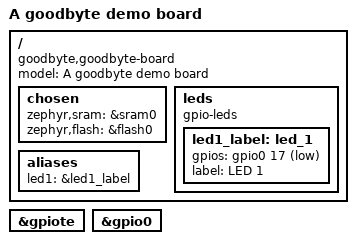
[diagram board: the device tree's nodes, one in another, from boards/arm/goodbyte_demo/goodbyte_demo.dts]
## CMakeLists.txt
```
cmake_minimum_required(VERSION 3.20.0)

list(APPEND BOARD_ROOT ${CMAKE_CURRENT_SOURCE_DIR})
find_package(Zephyr REQUIRED)
project(my_zephyr_app)

target_sources(app
    PRIVATE
        src/main.cpp
)
```

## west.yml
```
manifest:
  version: 0.13

  projects:
    - name: zephyr
      url: https://github.com/zephyrproject-rtos/zephyr
      revision: v3.7.0
      import:
        name-allowlist:
          - cmsis
          - hal_nordic
          - hal_stm32
        path-prefix: deps

  self:
    path: app
```

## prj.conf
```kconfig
CONFIG_GPIO=y
CONFIG_LOG=y
CONFIG_SHELL=y
CONFIG_GPIO_SHELL=y
```

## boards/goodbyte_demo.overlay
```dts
/ {
    aliases {
        led0 = &led1_label;
    };
};
```

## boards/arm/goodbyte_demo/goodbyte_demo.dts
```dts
/dts-v1/;

#include <nordic/nrf52832_qfaa.dtsi>

/ {
    model = "A goodbyte demo board";
    compatible = "goodbyte,goodbyte-board";

    chosen {
        zephyr,sram = &sram0;
        zephyr,flash = &flash0;
    };

    leds {
        compatible = "gpio-leds";
        led1_label: led_1 {
            gpios = <&gpio0 17 GPIO_ACTIVE_LOW>;
            label = "LED 1";
        };
    };

    aliases {
        led1 = &led1_label;
    };
};


&gpiote {
    status = "okay";
};

&gpio0 {
    status = "okay";
};
```

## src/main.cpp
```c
#include <zephyr/drivers/gpio.h>
#include <zephyr/kernel.h>
#include <zephyr/logging/log.h>

#define SLEEP_TIME_MS 1000

/* The devicetree node identifier for the "led1" alias. */
#define LED_NODE DT_ALIAS(led0)

static const struct gpio_dt_spec led = GPIO_DT_SPEC_GET(LED_NODE, gpios);

LOG_MODULE_REGISTER(main, LOG_LEVEL_INF);

int main(void)
{
    bool led_state = true;

    if (!gpio_is_ready_dt(&led)) return 0;

    if (gpio_pin_configure_dt(&led, GPIO_OUTPUT_ACTIVE) < 0) return 0;

    while (1) {
        if (gpio_pin_toggle_dt(&led) < 0) return 0;

        led_state = !led_state;
        LOG_INF("LED state: %s", led_state ? "ON" : "OFF");
        k_msleep(SLEEP_TIME_MS);
    }
    return 0;
}
```
